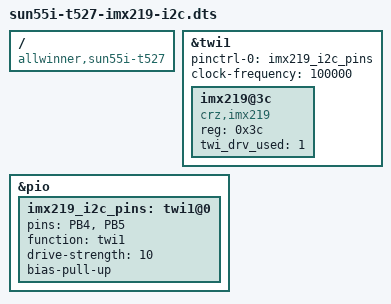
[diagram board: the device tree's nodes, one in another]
/dts-v1/;
/plugin/;

/ {
	compatible = "allwinner,sun55i-t527";
    fragment@0 {
        target = <&twi1>;  
        __overlay__ {
            #address-cells = <1>;
			#size-cells = <0>;
			pinctrl-0 = <&imx219_i2c_pins>;
			pinctrl-names = "default";
            clock-frequency = <100000>;
			status = "okay";
            imx219@3c { 
                compatible = "crz,imx219";
                reg = <0x3c>; 
                twi_drv_used = <1>;
                status = "okay";
            };
        };
    };

	fragment@1 {
		target = <&pio>;
		__overlay__ {
			imx219_i2c_pins: twi1@0 {
				pins = "PB4", "PB5";
				function = "twi1";
				drive-strength = <10>;
				bias-pull-up;
			};
		};
	};
};

